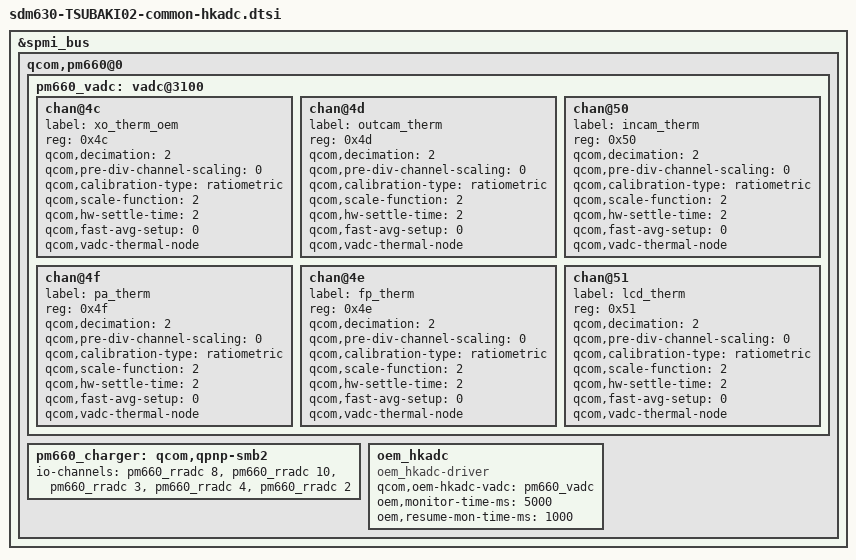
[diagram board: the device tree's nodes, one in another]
/*
 * This software is contributed or developed by KYOCERA Corporation.
 * (C) 2018 KYOCERA Corporation
 *
 * This program is free software; you can redistribute it and/or modify
 * it under the terms of the GNU General Public License version 2 and
 * only version 2 as published by the Free Software Foundation.
 *
 * This program is distributed in the hope that it will be useful,
 * but WITHOUT ANY WARRANTY; without even the implied warranty of
 * MERCHANTABILITY or FITNESS FOR A PARTICULAR PURPOSE.  See the
 * GNU General Public License for more details.
 */

&spmi_bus {

	qcom,pm660@0 {

		pm660_vadc: vadc@3100 {

			chan@4c {
				label = "xo_therm_oem";
				reg = <0x4c>;
				qcom,decimation = <2>;
				qcom,pre-div-channel-scaling = <0>;
				qcom,calibration-type = "ratiometric";
				qcom,scale-function = <2>;
				qcom,hw-settle-time = <2>;
				qcom,fast-avg-setup = <0>;
				qcom,vadc-thermal-node;
			};

			chan@4d {
				label = "outcam_therm";
				reg = <0x4d>;
				qcom,decimation = <2>;
				qcom,pre-div-channel-scaling = <0>;
				qcom,calibration-type = "ratiometric";
				qcom,scale-function = <2>;
				qcom,hw-settle-time = <2>;
				qcom,fast-avg-setup = <0>;
				qcom,vadc-thermal-node;
			};

			chan@50 {
				label = "incam_therm";
				reg = <0x50>;
				qcom,decimation = <2>;
				qcom,pre-div-channel-scaling = <0>;
				qcom,calibration-type = "ratiometric";
				qcom,scale-function = <2>;
				qcom,hw-settle-time = <2>;
				qcom,fast-avg-setup = <0>;
				qcom,vadc-thermal-node;
			};

			chan@4f {
				label = "pa_therm";
				reg = <0x4f>;
				qcom,decimation = <2>;
				qcom,pre-div-channel-scaling = <0>;
				qcom,calibration-type = "ratiometric";
				qcom,scale-function = <2>;
				qcom,hw-settle-time = <2>;
				qcom,fast-avg-setup = <0>;
				qcom,vadc-thermal-node;
			};

			chan@4e {
				label = "fp_therm";
				reg = <0x4e>;
				qcom,decimation = <2>;
				qcom,pre-div-channel-scaling = <0>;
				qcom,calibration-type = "ratiometric";
				qcom,scale-function = <2>;
				qcom,hw-settle-time = <2>;
				qcom,fast-avg-setup = <0>;
				qcom,vadc-thermal-node;
			};

			chan@51 {
				label = "lcd_therm";
				reg = <0x51>;
				qcom,decimation = <2>;
				qcom,pre-div-channel-scaling = <0>;
				qcom,calibration-type = "ratiometric";
				qcom,scale-function = <2>;
				qcom,hw-settle-time = <2>;
				qcom,fast-avg-setup = <0>;
				qcom,vadc-thermal-node;
			};
		};

		pm660_charger: qcom,qpnp-smb2 {
		          io-channels = <&pm660_rradc 8>,
                                        <&pm660_rradc 10>,
                                        <&pm660_rradc 3>,
                                        <&pm660_rradc 4>,
				        <&pm660_rradc 2>;
                          io-channel-names = "charger_temp",
						"charger_temp_max",
						"usbin_i",
						"usbin_v",
						"skin_temp";
		};

		oem_hkadc {
			compatible = "oem_hkadc-driver";
			qcom,oem-hkadc-vadc = <&pm660_vadc>;
			oem,monitor-time-ms = <5000>;
			oem,resume-mon-time-ms = <1000>;
		};
	};

};

